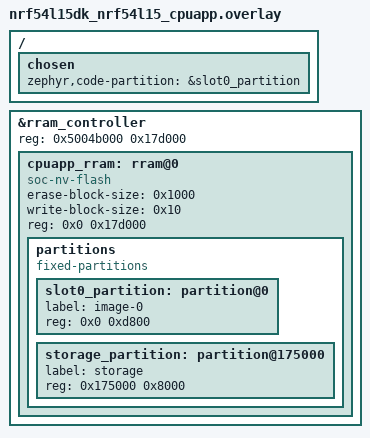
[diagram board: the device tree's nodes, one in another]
/ {
	chosen {
		zephyr,code-partition = &slot0_partition;
	};

};

/delete-node/ &cpuapp_rram;

&rram_controller {
	reg = < 0x5004b000 0x17d000 >;

	cpuapp_rram: rram@0 {
		compatible = "soc-nv-flash";
		erase-block-size = < 0x1000 >;
		write-block-size = < 0x10 >;
		reg = < 0x0 0x17d000 >;
		partitions {
			compatible = "fixed-partitions";
			#address-cells = < 0x1 >;
			#size-cells = < 0x1 >;
			slot0_partition: partition@0 {
				label = "image-0";
				reg = < 0x0 0xd800 >;
			};
			storage_partition: partition@175000 {
				label = "storage";
				reg = < 0x175000 0x8000 >;
			};
		};
	};
};
